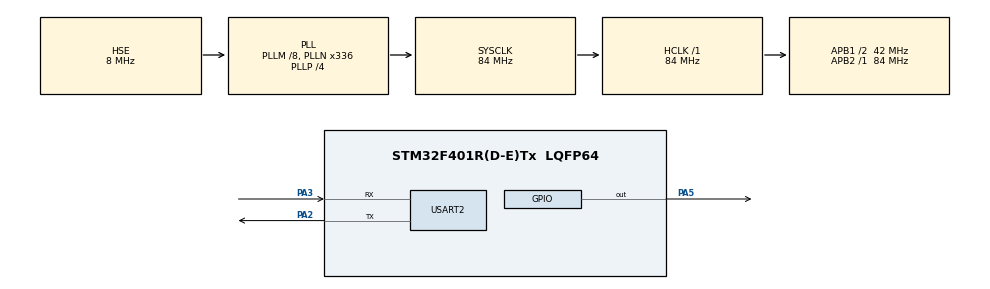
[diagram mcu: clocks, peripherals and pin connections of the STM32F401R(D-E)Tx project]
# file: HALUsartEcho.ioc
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FREERTOS.Tasks01=UartTask,25,256,StartUartTask,Default,NULL,Dynamic,NULL,NULL;LedTask,25,256,StartLedTask,Default,NULL,Dynamic,NULL,NULL
Mcu.Family=STM32F4
Mcu.Name=STM32F401R(D-E)Tx
Mcu.Package=LQFP64
NVIC.PriorityGroup=NVIC_PRIORITYGROUP_4
NVIC.TIM1_UP_TIM10_IRQn=true\:0\:0\:false\:false\:true\:false\:false\:true
NVIC.TimeBase=TIM1_UP_TIM10_IRQn
NVIC.TimeBaseIP=TIM1
PA2.Mode=Asynchronous
PA2.Signal=USART2_TX
PA3.Mode=Asynchronous
PA3.Signal=USART2_RX
PA5.Signal=GPIO_Output
PH0\ -\ OSC_IN.Mode=HSE-External-Oscillator
PH0\ -\ OSC_IN.Signal=RCC_OSC_IN
PH1\ -\ OSC_OUT.Mode=HSE-External-Oscillator
PH1\ -\ OSC_OUT.Signal=RCC_OSC_OUT
ProjectManager.HeapSize=0x200
ProjectManager.StackSize=0x400
ProjectManager.TargetToolchain=Makefile
RCC.48MHZClocksFreq_Value=48000000
RCC.AHBFreq_Value=84000000
RCC.APB1CLKDivider=RCC_HCLK_DIV2
RCC.APB1Freq_Value=42000000
RCC.APB1TimFreq_Value=84000000
RCC.APB2Freq_Value=84000000
RCC.APB2TimFreq_Value=84000000
RCC.CortexFreq_Value=84000000
RCC.HCLKFreq_Value=84000000
RCC.HSE_VALUE=8000000
RCC.HSI_VALUE=16000000
RCC.LSE_VALUE=32768
RCC.PLLM=8
RCC.PLLN=336
RCC.PLLP=RCC_PLLP_DIV4
RCC.PLLQ=7
RCC.PLLSourceVirtual=RCC_PLLSOURCE_HSE
RCC.SYSCLKFreq_VALUE=84000000
RCC.SYSCLKSource=RCC_SYSCLKSOURCE_PLLCLK
RCC.VCOOutputFreq_Value=336000000
USART2.VirtualMode=VM_ASYNC
VP_FREERTOS_VS_CMSIS_V2.Mode=CMSIS_V2
VP_SYS_VS_tim1.Mode=TIM1
board=NUCLEO-F401RE

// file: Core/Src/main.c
/* USER CODE BEGIN Header */
/**
	******************************************************************************
	* @file           : main.c
	* @brief          : Main program body
	******************************************************************************
	* @attention
	*
	* <h2><center>&copy; Copyright (c) 2021 STMicroelectronics.
	* All rights reserved.</center></h2>
	*
	* This software component is licensed by ST under BSD 3-Clause license,
	* the "License"; You may not use this file except in compliance with the
	* License. You may obtain a copy of the License at:
	*                        opensource.org/licenses/BSD-3-Clause
	*
	******************************************************************************
	*/
/* USER CODE END Header */
#include "main.h"
#include "cmsis_os.h"
#include "FreeRTOS.h"
#include "queue.h"
#include "string.h"
#include "stdlib.h"

#define MAX_MESSAGE_SIZE 128
#define DELAY_STRING "delay"

#define DEFAULT_DELAY 1000 // ms
#define BLINK_MESSAGE "Blinked\n\r"
#define MAX_BLINK 100

#define UART_USER_DELAY 5000 // ms

#define LED_PORT GPIOA
#define LED_PIN GPIO_PIN_5

UART_HandleTypeDef huart2;

/* Definitions for UartTask */
osThreadId_t UartTaskHandle;
const osThreadAttr_t UartTask_attributes = {
  .name = "UartTask",
  .stack_size = 256 * 4,
  .priority = (osPriority_t) osPriorityNormal1,
};
/* Definitions for LedTask */
osThreadId_t LedTaskHandle;
const osThreadAttr_t LedTask_attributes = {
  .name = "LedTask",
  .stack_size = 256 * 4,
  .priority = (osPriority_t) osPriorityNormal1,
};
/* USER CODE BEGIN PV */
xQueueHandle queueUsart;
xQueueHandle queueLed;

/* USER CODE END PV */

void SystemClock_Config(void);
static void MX_GPIO_Init(void);
static void MX_USART2_UART_Init(void);
void StartUartTask(void *argument);
void StartLedTask(void *argument);
void InitQueues(void);

int main(void)
{

  /* MCU Configuration--------------------------------------------------------*/

  /* Reset of all peripherals, Initializes the Flash interface and the Systick. */
  HAL_Init();

  /* Configure the system clock */
  SystemClock_Config();

  /* Initialize all configured peripherals */
  MX_GPIO_Init();
  MX_USART2_UART_Init();

  /* Init scheduler */
  osKernelInitialize();

  /* USER CODE BEGIN RTOS_QUEUES */
  CreateQueues();
  /* USER CODE END RTOS_QUEUES */

  /* Create the thread(s) */
  /* creation of UartTask */
  UartTaskHandle = osThreadNew(StartUartTask, NULL, &UartTask_attributes);

  /* creation of LedTask */
  LedTaskHandle = osThreadNew(StartLedTask, NULL, &LedTask_attributes);

  /* Start scheduler */
  osKernelStart();

  /* We should never get here as control is now taken by the scheduler */
  /* Infinite loop */
  while (1)
  {

	}
}

void SystemClock_Config(void)
{
  RCC_OscInitTypeDef RCC_OscInitStruct = {0};
  RCC_ClkInitTypeDef RCC_ClkInitStruct = {0};

  /** Configure the main internal regulator output voltage
  */
  __HAL_RCC_PWR_CLK_ENABLE();
  __HAL_PWR_VOLTAGESCALING_CONFIG(PWR_REGULATOR_VOLTAGE_SCALE2);
  /** Initializes the RCC Oscillators according to the specified parameters
  * in the RCC_OscInitTypeDef structure.
  */
  RCC_OscInitStruct.OscillatorType = RCC_OSCILLATORTYPE_HSE;
  RCC_OscInitStruct.HSEState = RCC_HSE_ON;
  RCC_OscInitStruct.PLL.PLLState = RCC_PLL_ON;
  RCC_OscInitStruct.PLL.PLLSource = RCC_PLLSOURCE_HSE;
  RCC_OscInitStruct.PLL.PLLM = 8;
  RCC_OscInitStruct.PLL.PLLN = 336;
  RCC_OscInitStruct.PLL.PLLP = RCC_PLLP_DIV4;
  RCC_OscInitStruct.PLL.PLLQ = 7;
  if (HAL_RCC_OscConfig(&RCC_OscInitStruct) != HAL_OK)
  {
	Error_Handler();
  }
  /** Initializes the CPU, AHB and APB buses clocks
  */
  RCC_ClkInitStruct.ClockType = RCC_CLOCKTYPE_HCLK|RCC_CLOCKTYPE_SYSCLK
							  |RCC_CLOCKTYPE_PCLK1|RCC_CLOCKTYPE_PCLK2;
  RCC_ClkInitStruct.SYSCLKSource = RCC_SYSCLKSOURCE_PLLCLK;
  RCC_ClkInitStruct.AHBCLKDivider = RCC_SYSCLK_DIV1;
  RCC_ClkInitStruct.APB1CLKDivider = RCC_HCLK_DIV2;
  RCC_ClkInitStruct.APB2CLKDivider = RCC_HCLK_DIV1;

  if (HAL_RCC_ClockConfig(&RCC_ClkInitStruct, FLASH_LATENCY_2) != HAL_OK)
  {
	Error_Handler();
  }
}

static void MX_USART2_UART_Init(void)
{

  huart2.Instance = USART2;
  huart2.Init.BaudRate = 115200;
  huart2.Init.WordLength = UART_WORDLENGTH_8B;
  huart2.Init.StopBits = UART_STOPBITS_1;
  huart2.Init.Parity = UART_PARITY_NONE;
  huart2.Init.Mode = UART_MODE_TX_RX;
  huart2.Init.HwFlowCtl = UART_HWCONTROL_NONE;
  huart2.Init.OverSampling = UART_OVERSAMPLING_16;
  if (HAL_UART_Init(&huart2) != HAL_OK)
  {
	Error_Handler();
  }

}

static void MX_GPIO_Init(void)
{
  GPIO_InitTypeDef GPIO_InitStruct = {0};

  /* GPIO Ports Clock Enable */
  __HAL_RCC_GPIOH_CLK_ENABLE();
  __HAL_RCC_GPIOA_CLK_ENABLE();

  /*Configure GPIO pin Output Level */
  HAL_GPIO_WritePin(GPIOA, GPIO_PIN_5, GPIO_PIN_RESET);

  /*Configure GPIO pin : PA5 */
  GPIO_InitStruct.Pin = GPIO_PIN_5;
  GPIO_InitStruct.Mode = GPIO_MODE_OUTPUT_PP;
  GPIO_InitStruct.Pull = GPIO_NOPULL;
  GPIO_InitStruct.Speed = GPIO_SPEED_FREQ_LOW;
  HAL_GPIO_Init(GPIOA, &GPIO_InitStruct);

}

/* USER CODE BEGIN 4 */
void CreateQueues(void) {
	queueUsart = xQueueCreate(5, MAX_MESSAGE_SIZE*sizeof(char)); // TODO add define
	queueLed = xQueueCreate(5, sizeof(uint32_t));
}

/* USER CODE END 4 */

void StartUartTask(void *argument)
{
  	char userBuff[MAX_MESSAGE_SIZE] = {0};
	char queueBuff[MAX_MESSAGE_SIZE] = {0};

	char rx_char;
	uint8_t i = 2;
	uint32_t delay = 0;
  	const char * delayStr = NULL;
	uint8_t uartStatus = HAL_OK;

	while (1) {
		i = 0;
    	rx_char = 0;

		if (xQueueReceive(queueUsart, queueBuff, 0)) {
			HAL_UART_Transmit(&huart2, queueBuff, MAX_MESSAGE_SIZE, HAL_MAX_DELAY);
			continue;
		}

		do {
			uartStatus = HAL_UART_Receive(&huart2, &rx_char, 1, UART_USER_DELAY);
			userBuff[i] = rx_char;
			++i;
		} while(uartStatus == HAL_OK && i < MAX_MESSAGE_SIZE - 3 && rx_char != '\r');

		if (strncmp(userBuff, DELAY_STRING, strlen(DELAY_STRING)) == 0) {
			delayStr = strchr(userBuff, 'y');
      		delay = atoi(++delayStr);
			if(delay) {
        		xQueueSend(queueLed, &delay, 2);
      		}
		}

		if (userBuff[0] != '\0') {
			strncpy(userBuff + i, "\n\r", 2);
			HAL_UART_Transmit(&huart2, userBuff, MAX_MESSAGE_SIZE, HAL_MAX_DELAY);
			memset(userBuff, 0, MAX_MESSAGE_SIZE);
		}

	}
}

void StartLedTask(void *argument)
{
	uint32_t delay = DEFAULT_DELAY;
	uint8_t blinkCounter = 0;
  	const char blinkMessage[128] = BLINK_MESSAGE;
	while(1) {
		if(xQueueReceive(queueLed, &delay, 0)) {
			blinkCounter = 0;
		}
		HAL_GPIO_TogglePin(LED_PORT, LED_PIN);
		osDelay(delay);

		if(++blinkCounter == MAX_BLINK) {
			xQueueSend(queueUsart, blinkMessage, 2);
      		blinkCounter = 0;
		}
	}
  /* USER CODE END StartLedTask */
}

 /**
  * @brief  Period elapsed callback in non blocking mode
  * @note   This function is called  when TIM1 interrupt took place, inside
  * HAL_TIM_IRQHandler(). It makes a direct call to HAL_IncTick() to increment
  * a global variable "uwTick" used as application time base.
  * @param  htim : TIM handle
  * @retval None
  */
void HAL_TIM_PeriodElapsedCallback(TIM_HandleTypeDef *htim)
{
  if (htim->Instance == TIM1) {
	HAL_IncTick();
  }
}

void Error_Handler(void)
{
	__disable_irq();
	while (1)
	{
	}
}

/************************ (C) COPYRIGHT STMicroelectronics *****END OF FILE****/
